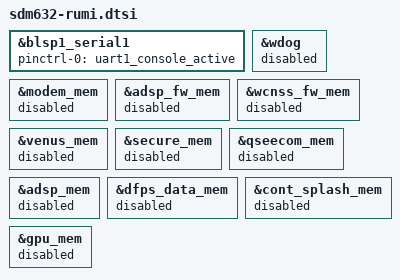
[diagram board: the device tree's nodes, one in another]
/*
 * Copyright (c) 2018, The Linux Foundation. All rights reserved.
 *
 * This program is free software; you can redistribute it and/or modify
 * it under the terms of the GNU General Public License version 2 and
 * only version 2 as published by the Free Software Foundation.
 *
 * This program is distributed in the hope that it will be useful,
 * but WITHOUT ANY WARRANTY; without even the implied warranty of
 * MERCHANTABILITY or FITNESS FOR A PARTICULAR PURPOSE.  See the
 * GNU General Public License for more details.
 */

&blsp1_serial1 {
	status = "ok";
	pinctrl-names = "default";
	pinctrl-0 = <&uart1_console_active>;
};

&wdog {
	status = "disabled";
};

&modem_mem {
	status = "disabled";
};

&adsp_fw_mem {
	status = "disabled";
};

&wcnss_fw_mem {
	status = "disabled";
};

&venus_mem {
	status = "disabled";
};

&secure_mem {
	status = "disabled";
};

&qseecom_mem {
	status = "disabled";
};

&adsp_mem {
	status = "disabled";
};

&dfps_data_mem {
	status = "disabled";
};

&cont_splash_mem {
	status = "disabled";
};

&gpu_mem {
	status = "disabled";
};
